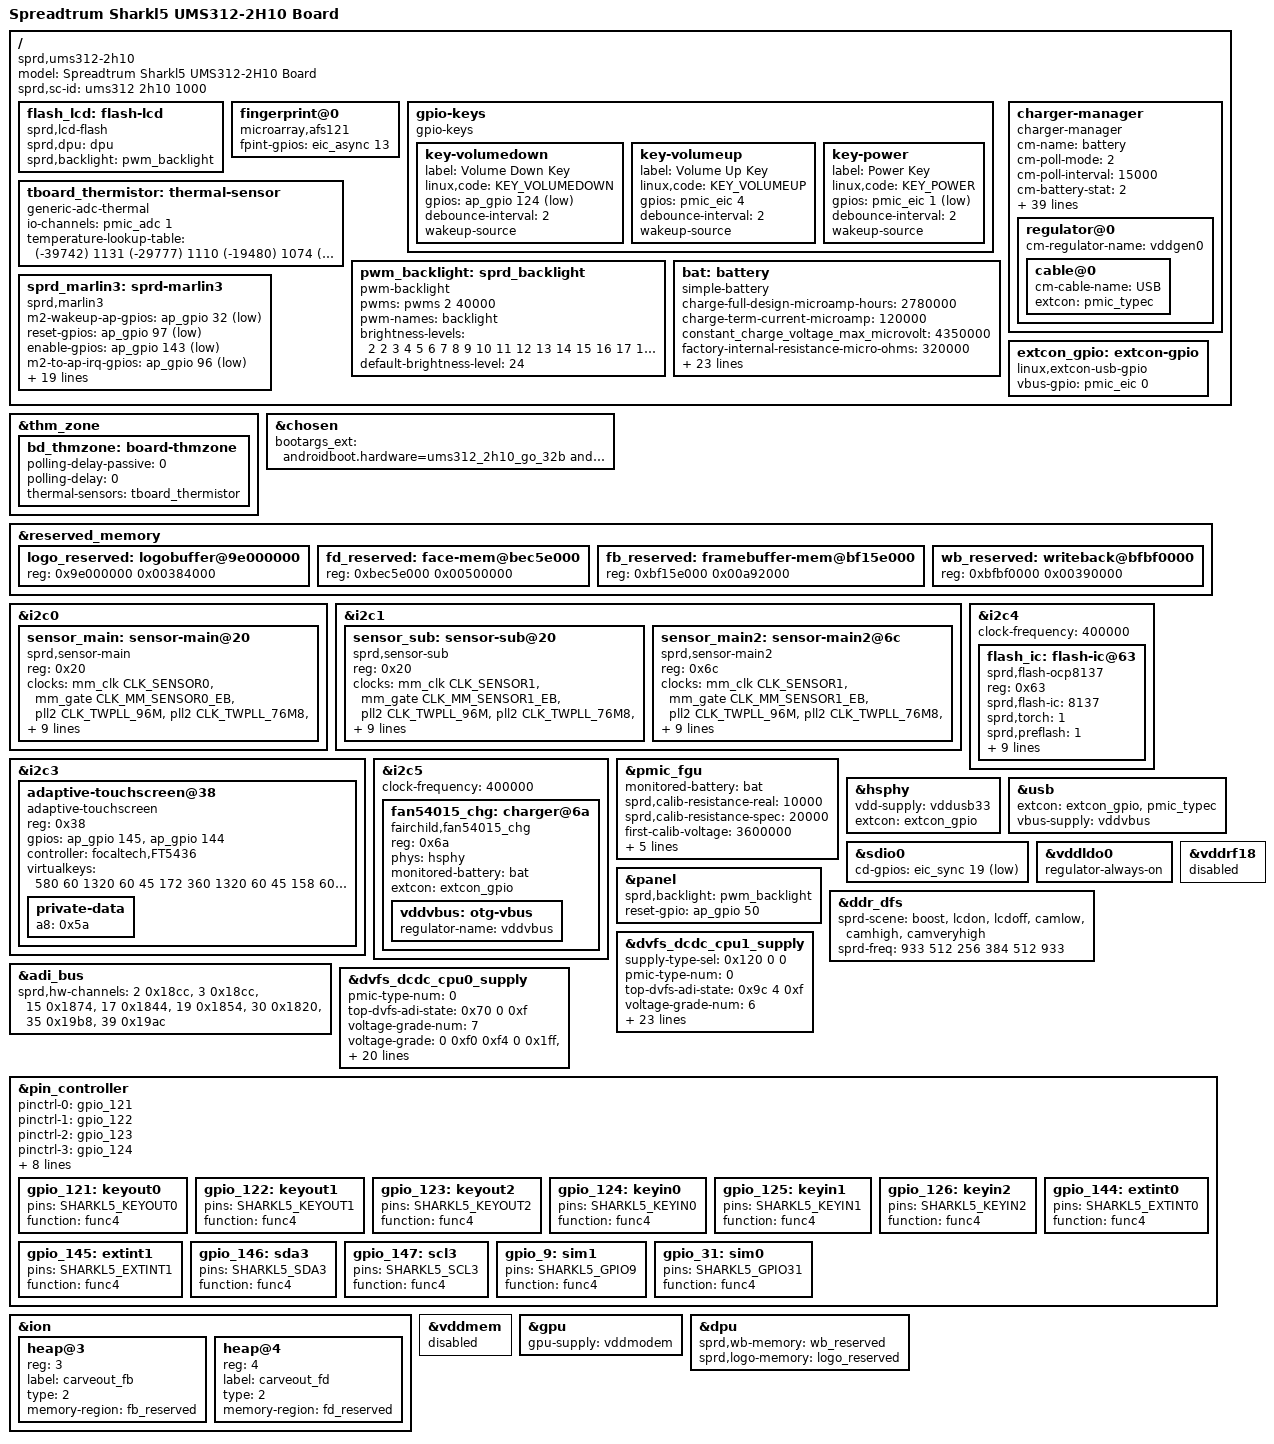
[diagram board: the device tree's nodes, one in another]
/dts-v1/;
/plugin/;

#include <dt-bindings/input/input.h>
#include <dt-bindings/gpio/gpio.h>
#include <dt-bindings/clock/sprd,sharkl5-clk.h>
#include <dt-bindings/mfd/sprd,sc2730-regs.h>
#include <dt-bindings/mfd/sprd,sc2730-mask.h>
#include "lcd/lcd_r61350_truly_mipi_hd.dtsi"
#include "lcd/lcd_ili9881c_truly_mipi_hd.dtsi"
#include "lcd/lcd_dummy_mipi.dtsi"

/ {
	model = "Spreadtrum Sharkl5 UMS312-2H10 Board";

	compatible = "sprd,ums312-2h10", "sprd,ums312";

	sprd,sc-id = "ums312 2h10 1000";

	fragment {
		target-path = "/";
		__overlay__ {
			flash_lcd: flash-lcd {
				compatible = "sprd,lcd-flash";
				sprd,dpu = <&dpu>;
				sprd,backlight = <&pwm_backlight>;
				status = "okay";
			};

			fingerprint@0 {
				compatible = "microarray,afs121";
				fpint-gpios = <&eic_async 13 0>;
			};

			gpio-keys {
				compatible = "gpio-keys";

				key-volumedown {
					label = "Volume Down Key";
					linux,code = <KEY_VOLUMEDOWN>;
					gpios = <&ap_gpio 124 GPIO_ACTIVE_LOW>;
					debounce-interval = <2>;
					wakeup-source;
				};

				key-volumeup {
					label = "Volume Up Key";
					linux,code = <KEY_VOLUMEUP>;
					gpios = <&pmic_eic 4 GPIO_ACTIVE_HIGH>;
					debounce-interval = <2>;
					wakeup-source;
				};

				key-power {
					label = "Power Key";
					linux,code = <KEY_POWER>;
					gpios = <&pmic_eic 1 GPIO_ACTIVE_LOW>;
					debounce-interval = <2>;
					wakeup-source;
				};
			};

			tboard_thermistor:thermal-sensor {
				compatible = "generic-adc-thermal";
				#thermal-sensor-cells = <0>;
				io-channels = <&pmic_adc 1>;
				io-channel-names = "sensor-channel";
				temperature-lookup-table = <	(-39742) 1131
								(-29777) 1110
								(-19480) 1074
								(-4679) 983
								10110 838
								24805 654
								44922 413
								54903 316
								64895 238
								74884 178
								84883 133
								94883 100
								104880 75
								114889 57
								124872 43 >;
			};

			pwm_backlight: sprd_backlight {
				compatible = "pwm-backlight";
				pwms = <&pwms 2 40000>;
				pwm-names = "backlight";
				brightness-levels = <
					      2   2   3   4   5   6   7   8   9
					 10  11  12  13  14  15  16  17  18  19
					 20  21  22  23  24  25  26  27  28  29
					 30  31  32  33  34  35  36  37  38  39
					 40  41  42  43  44  45  46  47  48  49
					 50  51  52  53  54  55  56  57  58  59
					 60  61  62  63  64  65  66  67  68  69
					 70  71  72  73  74  75  76  77  78  79
					 80  81  82  83  84  85  86  87  88  89
					 90  91  92  93  94  95  96  97  98  99
					100 101 102 103 104 105 106 107 108 109
					110 111 112 113 114 115 116 117 118 119
					120 121 122 123 124 125 126 127 128 129
					130 131 132 133 134 135 136 137 138 139
					140 141 142 143 144 145 146 147 148 149
					150 151 152 153 154 155 156 157 158 159
					160 161 162 163 164 165 166 167 168 169
					170 171 172 173 174 175 176 177 178 179
					180 181 182 183 184 185 186 187 188 189
					190 191 192 193 194 195 196 197 198 199
					200 201 202 203 204 205 206 207 208 209
					210 211 212 213 214 215 216 217 218 219
					220 221 222 223 224 225 226 227 228 229
					230 231 232 233 234 235 236 237 238 239
					240 241 242 243 244 245 246 247 247 247
					247 247 247 247 247 247 247
					>;
				default-brightness-level = <24>;
			};

			bat: battery {
				compatible = "simple-battery";
				charge-full-design-microamp-hours = <2780000>;
				charge-term-current-microamp = <120000>;
				constant_charge_voltage_max_microvolt = <4350000>;
				factory-internal-resistance-micro-ohms = <320000>;
				voltage-min-design-microvolt = <3450000>;
				ocv-capacity-celsius = <20>;
				ocv-capacity-table-0 = <4360000 100>, <4249000 95>, <4189000 90>,
							<4133000 85>, <4081000 80>, <4034000 75>,
							<3991000 70>, <3953000 65>, <3910000 60>,
							<3866000 55>, <3836000 50>, <3813000 45>,
							<3795000 40>, <3782000 35>, <3774000 30>,
							<3765000 25>, <3750000 20>, <3726000 15>,
							<3687000 10>, <3658000 5>, <3400000 0>;
				voltage-temp-table = <1095000 800>, <986000 850>, <878000 900>,
							<775000 950>, <678000 1000>, <590000 1050>,
							<510000 1100>, <440000 1150>, <378000 1200>,
							<324000 1250>, <278000 1300>, <238000 1350>,
							<204000 1400>, <175000 1450>, <150000 1500>,
							<129000 1550>, <111000 1600>, <96000 1650>;
				capacity-temp-table = <25 100>, <10 97>, <(-10) 60>;
				resistance-temp-table = <20 100>, <10 243>, <(-10) 468>;
				charge-sdp-current-microamp = <500000 500000>;
				charge-dcp-current-microamp = <1200000 3000000>;
				charge-cdp-current-microamp = <1150000 1150000>;
				charge-unknown-current-microamp = <500000 500000>;
			};

			charger-manager {
				compatible = "charger-manager";
				cm-name = "battery";
				cm-poll-mode = <2>;
				cm-poll-interval = <15000>;
				cm-battery-stat = <2>;

				cm-fullbatt-vchkdrop-ms = <30000>;
				cm-fullbatt-vchkdrop-volt = <60000>;
				cm-fullbatt-voltage = <4300000>;
				cm-fullbatt-current = <120000>;
				cm-fullbatt-capacity = <100>;

				cm-chargers = "fan54015_charger";
				cm-fuel-gauge = "sc27xx-fgu";

				/* in deci centigrade */
				cm-battery-cold = <200>;
				cm-battery-cold-in-minus;
				cm-battery-hot = <800>;
				cm-battery-temp-diff = <100>;

				/* Allow charging for 6hr */
				cm-charging-max = <18000000>;

				/* the interval to feed charger watchdog */
				cm-wdt-interval = <60>;

				/* drop voltage in microVolts to allow shutdown */
				cm-shutdown-voltage = <3100000>;

				/* when 99% of the time is exceeded, it will be forced to 100% */
				cm-tickle-time-out = <1500>;

				/* how much time to allow capacity change */
				cm-one-cap-time = <30>;

				/* when the safe charging voltage is exceeded, stop charging */
				cm-charge-voltage-max = <6500000>;
				/* drop voltage in microVolts to restart charging */
				cm-charge-voltage-drop = <700000>;
				cm-thermal-zone = "board-thmzone";
				cm-dcp-jeita-temp-table = <1000 1030 0 4350000>, <1150 1180 700000 4350000>,
					<1450 1420 1200000 4350000>, <1600 1570 700000 4100000>;
				cm-sdp-jeita-temp-table = <1000 1030 0 4350000>, <1150 1180 500000 4350000>,
					<1450 1420 500000 4350000>, <1600 1570 500000 4100000>;
				cm-cdp-jeita-temp-table = <1000 1030 0 4350000>, <1150 1180 700000 4350000>,
					<1450 1420 1150000 4350000>, <1600 1570 700000 4100000>;
				cm-unknown-jeita-temp-table = <1000 1030 0 4350000>, <1150 1180 500000 4350000>,
					<1450 1420 500000 4350000>, <1600 1570 500000 4100000>;

				monitored-battery = <&bat>;

				cm-cap-remap-table = <1 2 3>, <2 3 2>, <98 99 2>, <99 100 3>;

				regulator@0 {
					cm-regulator-name = "vddgen0";
					cable@0 {
						cm-cable-name = "USB";
						extcon = <&pmic_typec>;
					};
				};
			};

			sprd_marlin3: sprd-marlin3 {
				compatible = "sprd,marlin3";
				m2-wakeup-ap-gpios = <&ap_gpio 32 GPIO_ACTIVE_LOW>;
				reset-gpios = <&ap_gpio 97 GPIO_ACTIVE_LOW>;
				enable-gpios = <&ap_gpio 143 GPIO_ACTIVE_LOW>;
				m2-to-ap-irq-gpios = <&ap_gpio 96 GPIO_ACTIVE_LOW>;
				xtal-26m-clk-type = "TSX";
				avdd12-supply = <&vddwcn>;
				avdd33-supply = <&vddwifipa>;
				dcxo18-supply = <&vddsim2>;

				clock-names = "clk_32k","source","enable";
				clocks = <&aon_clk CLK_AUX0>,
					 <&ext_32k>,
					 <&aonapb_gate CLK_AUX0_EB>;

				sdhci-name = <&sdio1>;
				sprd,btwf-file-name = "/dev/block/platform/soc/soc:ap-apb/71400000.sdio/by-name/wcnmodem";
				sprd,gnss-file-name = "/dev/block/platform/soc/soc:ap-apb/71400000.sdio/by-name/gnssmodem";
				adma-tx;
				adma-rx;
				/*
				 * bound parameter:
				 * [0]:addr offset, [1]:mask, [2]:unboundval, [3]:boundval
				 */
				avdd12-parent-bound-chip = <REG_ANA_SLP_DCDC_PD_CTRL MASK_ANA_SLP_DCDCGEN1_PD_EN 0x0 MASK_ANA_SLP_DCDCGEN1_PD_EN>;
				avdd12-bound-wbreq = <REG_ANA_LDO_XTL_EN10 MASK_ANA_LDO_VDDWCN_EXT_XTL3_EN 0x0 MASK_ANA_LDO_VDDWCN_EXT_XTL3_EN>;
				avdd33-bound-wbreq = <REG_ANA_LDO_XTL_EN11 MASK_ANA_LDO_VDDWIFIPA_EXT_XTL3_EN 0x0 MASK_ANA_LDO_VDDWIFIPA_EXT_XTL3_EN>;
			};

			extcon_gpio: extcon-gpio {
				compatible = "linux,extcon-usb-gpio";
				vbus-gpio = <&pmic_eic 0 GPIO_ACTIVE_HIGH>;
		        };

		};
	};
};

&thm_zone {
	bd_thmzone: board-thmzone {
		polling-delay-passive = <0>;
		polling-delay = <0>;
		thermal-sensors = <&tboard_thermistor>;
	};
};

&chosen {
	bootargs_ext = "androidboot.hardware=ums312_2h10_go_32b androidboot.dtbo_idx=0";
};

&reserved_memory {
	logo_reserved: logobuffer@9e000000{
		reg = <0x9e000000 0x00384000>;
	};

	fd_reserved: face-mem@bec5e000{
		reg = <0xbec5e000 0x00500000>;
	};

	fb_reserved: framebuffer-mem@bf15e000{
		reg = <0xbf15e000 0x00a92000>;
	};

	wb_reserved: writeback@bfbf0000{
		reg = <0xbfbf0000 0x00390000>;
	};

};

&i2c0 {
	status = "okay";

	sensor_main: sensor-main@20 {
		compatible = "sprd,sensor-main";
		reg = <0x20>;

		clock-names = "clk_src","sensor_eb",
			"clk_96m","clk_76m8",
			"clk_48m","clk_26m";
		clocks = <&mm_clk CLK_SENSOR0>,<&mm_gate CLK_MM_SENSOR0_EB>,
			<&pll2 CLK_TWPLL_96M>,<&pll2 CLK_TWPLL_76M8>,
			<&pll2 CLK_TWPLL_48M>,<&ext_26m>;
		vddio-supply = <&vddcamio>;
		vddcama-supply = <&vddcama0>;
		vddcamd-supply = <&vddcamd0>;
		vddcammot-supply = <&vddcammot>;
		sprd,phyid = <0>;
		csi = <&csi0>;
		reset-gpios = <&ap_gpio 44 0>;
		power-down-gpios = <&ap_gpio 46 0>;

		status = "okay";
	};
};

&i2c1 {
	status = "okay";

	sensor_sub: sensor-sub@20 {
		compatible = "sprd,sensor-sub";
		reg = <0x20>;

		clock-names = "clk_src","sensor_eb",
			"clk_96m","clk_76m8",
			"clk_48m","clk_26m";
		clocks = <&mm_clk CLK_SENSOR1>,<&mm_gate CLK_MM_SENSOR1_EB>,
			<&pll2 CLK_TWPLL_96M>,<&pll2 CLK_TWPLL_76M8>,
			<&pll2 CLK_TWPLL_48M>,<&ext_26m>;
		vddio-supply = <&vddcamio>;
		vddcama-supply = <&vddcama0>;
		vddcamd-supply = <&vddcamd0>;
		vddcammot-supply = <&vddcammot>;
		sprd,phyid = <4>;
		csi = <&csi1>;
		reset-gpios = <&ap_gpio 41 0>;
		power-down-gpios = <&ap_gpio 40 0>;

		status = "okay";
	};

	sensor_main2: sensor-main2@6c {
		compatible = "sprd,sensor-main2";
		reg = <0x6c>;

		clock-names = "clk_src","sensor_eb",
			"clk_96m","clk_76m8",
			"clk_48m","clk_26m";
		clocks = <&mm_clk CLK_SENSOR1>,<&mm_gate CLK_MM_SENSOR1_EB>,
			<&pll2 CLK_TWPLL_96M>,<&pll2 CLK_TWPLL_76M8>,
			<&pll2 CLK_TWPLL_48M>,<&ext_26m>;
		vddio-supply = <&vddcamio>;
		vddcama-supply = <&vddcama1>;
		vddcamd-supply = <&vddcamd1>;
		vddcammot-supply = <&vddcammot>;
		sprd,phyid = <3>;
		csi = <&csi1>;
		reset-gpios = <&ap_gpio 45 0>;
		power-down-gpios = <&ap_gpio 47 0>;

		status = "okay";
	};
};

&i2c3 {
	status = "okay";

	adaptive-touchscreen@38 {
		compatible = "adaptive-touchscreen";
		reg = <0x38>;
		gpios = <&ap_gpio 145 GPIO_ACTIVE_HIGH
			&ap_gpio 144 GPIO_ACTIVE_HIGH>;
		controller = "focaltech,FT5436";
		virtualkeys = <580 60 1320 60 45
				172 360 1320 60 45
				158 600 1320 60 45>;
		private-data {
			a8 = /bits/ 8 <0x5a>;
		};
	};
};

&i2c4 {
	status = "okay";
	clock-frequency = <400000>;

	flash_ic: flash-ic@63 {
		compatible = "sprd,flash-ocp8137";
		reg = <0x63>;
		sprd,flash-ic = <8137>;
		sprd,torch = <1>;
		sprd,preflash = <1>;
		sprd,highlight = <1>;
		sprd,torch-level = <128>;
		sprd,preflash-level = <128>;
		sprd,highlight-level = <128>;
		sprd,lvfm-enable = <1>;
		flash-torch-en-gpios = <&ap_gpio 136 0>;
		flash-chip-en-gpios = <&ap_gpio 135 0>;
		flash-en-gpios = <&ap_gpio 137 0>;
		flash-sync-gpios = <&ap_gpio 138 0>;
	};
};

&i2c5 {
	status = "okay";
	clock-frequency = <400000>;

	fan54015_chg: charger@6a {
		compatible = "fairchild,fan54015_chg";
		reg = <0x6a>;
		phys = <&hsphy>;
		monitored-battery = <&bat>;
		extcon = <&extcon_gpio>;
		vddvbus:otg-vbus {
			regulator-name = "vddvbus";
		};
	};
};

&pmic_fgu {
	monitored-battery = <&bat>;
	sprd,calib-resistance-real = <10000>;
	sprd,calib-resistance-spec = <20000>;
	first-calib-voltage = <3600000>;
	first-calib-capacity = <40>;
	fgu-capacity-track;
	fullbatt-track-end-vol = <4295>;
	fullbatt-track-end-cur = <130>;
	phys = <&hsphy>;
};

&hsphy {
	vdd-supply = <&vddusb33>;
	extcon = <&extcon_gpio>;
};

&usb {
	extcon = <&extcon_gpio>, <&pmic_typec>;
	vbus-supply = <&vddvbus>;
};

&sdio0 {
	cd-gpios = <&eic_sync 19 GPIO_ACTIVE_LOW>;
};

&vddldo0 {
	regulator-always-on;
};

&panel {
	sprd,backlight = <&pwm_backlight>;
	reset-gpio = <&ap_gpio 50 GPIO_ACTIVE_HIGH>;
};

&ddr_dfs {
	sprd-scene = "boost", "lcdon", "lcdoff", "camlow",
		"camhigh", "camveryhigh";
	sprd-freq = <933 512 256 384 512 933>;
};

&adi_bus {
	sprd,hw-channels = <2 0x18cc>, <3 0x18cc>, <15 0x1874>,
			   <17 0x1844>, <19 0x1854>, <30 0x1820>, <35 0x19b8>,
			   <39 0x19ac>;
};

&vddrf18 {
	status = "disabled";
};

&dvfs_dcdc_cpu0_supply {
	pmic-type-num = <0>;
	top-dvfs-adi-state = <0x70 0 0xf>;
	voltage-grade-num = <7>;
	voltage-grade = <0 0xf0 0xf4 0 0x1ff>,
			<1 0xf0 0xf4 9 0x1ff>,
			<2 0x100 0xf4 18 0x1ff>,
			<3 0x110 0xf8 0 0x1ff>,
			<4 0x120 0xf8 9 0x1ff>,
			<5 0x130 0xf8 18 0x1ff>,
			<6 0x140 0xfc 0 0x1ff>;
	voltage-up-delay = <50 0x58 0 0xffff 0x600>,
			<100 0x58 16 0xffff 0xa00>,
			<150 0x54 0 0xffff 0xf00>,
			<200 0x54 16 0xffff 0x1400>,
			<250 0x50 0 0xffff 0x1900>,
			<300 0x50 16 0xffff 0x1e00>,
			<350 0x110 0 0xffff 0x2300>;
	voltage-down-delay = <50 0x64 0 0xffff 0x600>,
			<100 0x64 16 0xffff 0xa00>,
			<150 0x60 0 0xffff 0xf00>,
			<200 0x60 16 0xffff 0x1400>,
			<250 0x5c 0 0xffff 0x1900>,
			<300 0x5c 16 0xffff 0x1e00>,
			<350 0x114 0 0xffff 0x2300>;
	tuning-latency-us = <0>;
	chnl-in-i2c = <0>;
	slew-rate = <9375>; /* 9375uV/us */
};

&dvfs_dcdc_cpu1_supply {
	supply-type-sel = <0x120 0 0>;
	pmic-type-num = <0>;
	top-dvfs-adi-state = <0x9c 4 0xf>;
	voltage-grade-num = <6>;
	voltage-grade = <0 0xf0 0x100 0 0x1ff>,
			<1 0x100 0x100 9 0x1ff>,
			<2 0x110 0x100 18 0x1ff>,
			<3 0x120 0x104 0 0x1ff>,
			<4 0x130 0x104 9 0x1ff>,
			<5 0x140 0x104 18 0x1ff>;
	voltage-up-delay = <50 0x84 0 0xffff 0x600>,
			<100 0x84 16 0xffff 0xa00>,
			<150 0x80 0 0xffff 0xf00>,
			<200 0x80 16 0xffff 0x1400>,
			<250 0x7c 0 0xffff 0x1900>,
			<300 0x7c 16 0xffff 0x1e00>,
			<350 0x118 0 0xffff 0x2300>;
	voltage-down-delay = <50 0x90 0 0xffff 0x600>,
			<100 0x90 16 0xffff 0xa00>,
			<150 0x8c 0 0xffff 0xf00>,
			<200 0x8c 16 0xffff 0x1400>,
			<250 0x88 0 0xffff 0x1900>,
			<300 0x88 16 0xffff 0x1e00>,
			<350 0x11c 0 0xffff 0x2300>;
	tuning-latency-us = <0>;
	chnl-in-i2c = <0>;
	slew-rate = <9375>; /* 9375uV/us */
};

&pin_controller {
	pinctrl-names =
	/* keyout0 ~ keyout2 */
	"gpio_121", "gpio_122", "gpio_123",
	/* keyin0 ~ keyin2 */
	"gpio_124", "gpio_125", "gpio_126",
	/* extint0, extint1, sda3, scl3 */
	"gpio_144", "gpio_145", "gpio_146", "gpio_147",
	/* sim0_det, sim1_det */
	"gpio_9", "gpio_31";
	pinctrl-0 = <&gpio_121>;
	pinctrl-1 = <&gpio_122>;
	pinctrl-2 = <&gpio_123>;
	pinctrl-3 = <&gpio_124>;
	pinctrl-4 = <&gpio_125>;
	pinctrl-5 = <&gpio_126>;
	pinctrl-6 = <&gpio_144>;
	pinctrl-7 = <&gpio_145>;
	pinctrl-8 = <&gpio_146>;
	pinctrl-9 = <&gpio_147>;
	pinctrl-10 = <&gpio_9>;
	pinctrl-11 = <&gpio_31>;

	gpio_121: keyout0 {
		pins = "SHARKL5_KEYOUT0";
		function = "func4";
	};

	gpio_122: keyout1 {
		pins = "SHARKL5_KEYOUT1";
		function = "func4";
	};

	gpio_123: keyout2 {
		pins = "SHARKL5_KEYOUT2";
		function = "func4";
	};

	gpio_124: keyin0 {
		pins = "SHARKL5_KEYIN0";
		function = "func4";
	};

	gpio_125: keyin1 {
		pins = "SHARKL5_KEYIN1";
		function = "func4";
	};

	gpio_126: keyin2 {
		pins = "SHARKL5_KEYIN2";
		function = "func4";
	};

	gpio_144: extint0 {
		pins = "SHARKL5_EXTINT0";
		function = "func4";
	};

	gpio_145: extint1 {
		pins = "SHARKL5_EXTINT1";
		function = "func4";
	};

	gpio_146: sda3 {
		pins = "SHARKL5_SDA3";
		function = "func4";
	};

	gpio_147: scl3 {
		pins = "SHARKL5_SCL3";
		function = "func4";
	};

	gpio_9: sim1 {
		pins = "SHARKL5_GPIO9";
		function = "func4";
	};

	gpio_31: sim0 {
		pins = "SHARKL5_GPIO31";
		function = "func4";
	};
};

&ion {
	heap@3 {
		reg = <3>;
		label = "carveout_fb";
		type = <2>;
		memory-region = <&fb_reserved>;
	};

	heap@4 {
		reg = <4>;
		label = "carveout_fd";
		type = <2>;
		memory-region = <&fd_reserved>;
	};
};

&vddmem {
	status = "disabled";
};

&gpu {
	gpu-supply = <&vddmodem>;
};

&dpu {
	sprd,wb-memory = <&wb_reserved>;
	sprd,logo-memory = <&logo_reserved>;
};
